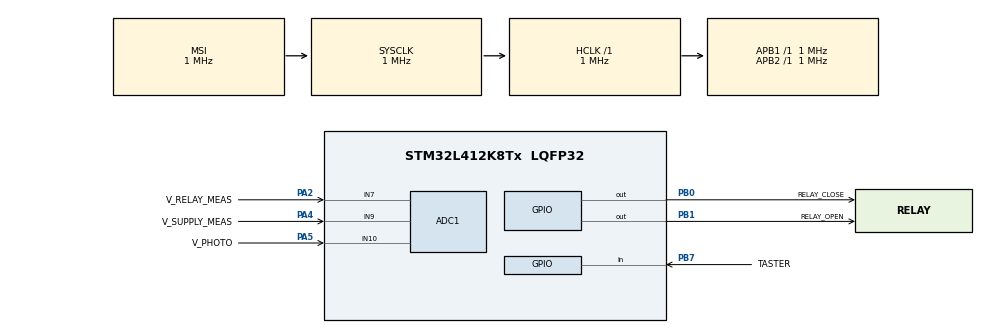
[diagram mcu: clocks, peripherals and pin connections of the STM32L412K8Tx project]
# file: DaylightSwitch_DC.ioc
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ADC1.Channel-0\#ChannelRegularConversion=ADC_CHANNEL_7
ADC1.Channel-1\#ChannelRegularConversion=ADC_CHANNEL_9
ADC1.Channel-2\#ChannelRegularConversion=ADC_CHANNEL_10
ADC1.Channel-3\#ChannelRegularConversion=ADC_CHANNEL_VREFINT
ADC1.ClockPrescaler=ADC_CLOCK_ASYNC_DIV4
ADC1.EOCSelection=ADC_EOC_SEQ_CONV
ADC1.NbrOfConversion=4
ADC1.NbrOfConversionFlag=1
ADC1.OffsetNumber-0\#ChannelRegularConversion=ADC_OFFSET_NONE
ADC1.OffsetNumber-1\#ChannelRegularConversion=ADC_OFFSET_NONE
ADC1.OffsetNumber-2\#ChannelRegularConversion=ADC_OFFSET_NONE
ADC1.OffsetNumber-3\#ChannelRegularConversion=ADC_OFFSET_NONE
ADC1.Overrun=ADC_OVR_DATA_OVERWRITTEN
ADC1.Rank-0\#ChannelRegularConversion=1
ADC1.Rank-1\#ChannelRegularConversion=2
ADC1.Rank-2\#ChannelRegularConversion=3
ADC1.Rank-3\#ChannelRegularConversion=4
ADC1.SamplingTime-0\#ChannelRegularConversion=ADC_SAMPLETIME_640CYCLES_5
ADC1.SamplingTime-1\#ChannelRegularConversion=ADC_SAMPLETIME_640CYCLES_5
ADC1.SamplingTime-2\#ChannelRegularConversion=ADC_SAMPLETIME_640CYCLES_5
ADC1.SamplingTime-3\#ChannelRegularConversion=ADC_SAMPLETIME_640CYCLES_5
ADC1.master=1
CRC.InputDataFormat=CRC_INPUTDATA_FORMAT_WORDS
Dma.ADC1.0.Direction=DMA_PERIPH_TO_MEMORY
Dma.ADC1.0.Instance=DMA1_Channel1
Dma.ADC1.0.MemDataAlignment=DMA_MDATAALIGN_HALFWORD
Dma.ADC1.0.MemInc=DMA_MINC_ENABLE
Dma.ADC1.0.Mode=DMA_NORMAL
Dma.ADC1.0.PeriphDataAlignment=DMA_PDATAALIGN_HALFWORD
Dma.ADC1.0.PeriphInc=DMA_PINC_DISABLE
Dma.ADC1.0.Priority=DMA_PRIORITY_MEDIUM
Dma.Request0=ADC1
Mcu.Family=STM32L4
Mcu.Name=STM32L412K8Tx
Mcu.Package=LQFP32
NVIC.ADC1_2_IRQn=true\:2\:0\:true\:false\:true\:true\:true
NVIC.DMA1_Channel1_IRQn=true\:0\:0\:true\:false\:true\:false\:true
NVIC.PriorityGroup=NVIC_PRIORITYGROUP_2
PA13\ (JTMS/SWDIO).Mode=Trace_Asynchronous_SW
PA13\ (JTMS/SWDIO).Signal=SYS_JTMS-SWDIO
PA14\ (JTCK/SWCLK).Mode=Trace_Asynchronous_SW
PA14\ (JTCK/SWCLK).Signal=SYS_JTCK-SWCLK
PA2.GPIO_Label=V_RELAY_MEAS
PA2.Signal=ADCx_IN7
PA4.GPIO_Label=V_SUPPLY_MEAS
PA4.Signal=ADCx_IN9
PA5.GPIO_Label=V_PHOTO
PA5.Signal=ADCx_IN10
PB0.GPIO_Label=RELAY_CLOSE
PB0.Signal=GPIO_Output
PB1.GPIO_Label=RELAY_OPEN
PB1.Signal=GPIO_Output
PB3\ (JTDO/TRACESWO).Mode=Trace_Asynchronous_SW
PB3\ (JTDO/TRACESWO).Signal=SYS_JTDO-SWO
PB7.GPIO_Label=TASTER
PB7.Signal=GPIO_Input
ProjectManager.HeapSize=0x600
ProjectManager.StackSize=0x600
ProjectManager.TargetToolchain=STM32CubeIDE
RCC.ADCFreq_Value=1000000
RCC.AHBFreq_Value=1000000
RCC.APB1Freq_Value=1000000
RCC.APB1TimFreq_Value=1000000
RCC.APB2Freq_Value=1000000
RCC.APB2TimFreq_Value=1000000
RCC.CortexFreq_Value=1000000
RCC.HCLKFreq_Value=1000000
RCC.HSE_VALUE=8000000
RCC.HSI48_VALUE=48000000
RCC.HSI_VALUE=16000000
RCC.LSE_VALUE=32768
RCC.MSIClockRange=RCC_MSIRANGE_4
RCC.MSI_VALUE=1000000
RCC.SYSCLKFreq_VALUE=1000000
RCC.USBFreq_Value=1000000
RCC.VCOOutputFreq_Value=8000000
SH.ADCx_IN10.0=ADC1_IN10,IN10-Single-Ended
SH.ADCx_IN7.0=ADC1_IN7,IN7-Single-Ended
SH.ADCx_IN9.0=ADC1_IN9,IN9-Single-Ended
VP_ADC1_Vref_Input.Mode=IN-Vrefint
VP_CRC_VS_CRC.Mode=CRC_Activate
board=custom

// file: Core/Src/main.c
/* USER CODE BEGIN Header */
/**
  ******************************************************************************
  * @file           : main.c
  * @brief          : Main program body
  ******************************************************************************
  * @attention
  *
  * <h2><center>&copy; Copyright (c) 2020 STMicroelectronics.
  * All rights reserved.</center></h2>
  *
  * This software component is licensed by ST under BSD 3-Clause license,
  * the "License"; You may not use this file except in compliance with the
  * License. You may obtain a copy of the License at:
  *                        opensource.org/licenses/BSD-3-Clause
  *
  ******************************************************************************
  */
/* USER CODE END Header */

#include "main.h"

ADC_HandleTypeDef hadc1;
DMA_HandleTypeDef hdma_adc1;

CRC_HandleTypeDef hcrc;

/* USER CODE BEGIN PV */
extern void doCpp(void);
/* USER CODE END PV */

void SystemClock_Config(void);
static void MX_GPIO_Init(void);
static void MX_DMA_Init(void);
static void MX_ADC1_Init(void);
static void MX_CRC_Init(void);

int main(void)
{
  /* USER CODE BEGIN 1 */
  CoreDebug->DEMCR |= CoreDebug_DEMCR_TRCENA_Msk;
  DWT->CYCCNT = 0;
  DWT->CTRL |= DWT_CTRL_CYCCNTENA_Msk;
  /* USER CODE END 1 */

  /* MCU Configuration--------------------------------------------------------*/

  /* Reset of all peripherals, Initializes the Flash interface and the Systick. */
  HAL_Init();

  /* Configure the system clock */
  SystemClock_Config();

  /* Initialize all configured peripherals */
  MX_GPIO_Init();
  MX_DMA_Init();
  MX_ADC1_Init();
  MX_CRC_Init();
  /* USER CODE BEGIN 2 */

  doCpp();  // --> This function should never return..
  /* USER CODE END 2 */

  /* Infinite loop */
  while (1)
  {

  }
}

void SystemClock_Config(void)
{
  RCC_OscInitTypeDef RCC_OscInitStruct = {0};
  RCC_ClkInitTypeDef RCC_ClkInitStruct = {0};
  RCC_PeriphCLKInitTypeDef PeriphClkInit = {0};

  /** Configure the main internal regulator output voltage
  */
  if (HAL_PWREx_ControlVoltageScaling(PWR_REGULATOR_VOLTAGE_SCALE1) != HAL_OK)
  {
    Error_Handler();
  }
  /** Initializes the CPU, AHB and APB busses clocks
  */
  RCC_OscInitStruct.OscillatorType = RCC_OSCILLATORTYPE_MSI;
  RCC_OscInitStruct.MSIState = RCC_MSI_ON;
  RCC_OscInitStruct.MSICalibrationValue = 0;
  RCC_OscInitStruct.MSIClockRange = RCC_MSIRANGE_4;
  RCC_OscInitStruct.PLL.PLLState = RCC_PLL_NONE;
  if (HAL_RCC_OscConfig(&RCC_OscInitStruct) != HAL_OK)
  {
    Error_Handler();
  }
  /** Initializes the CPU, AHB and APB busses clocks
  */
  RCC_ClkInitStruct.ClockType = RCC_CLOCKTYPE_HCLK|RCC_CLOCKTYPE_SYSCLK
                              |RCC_CLOCKTYPE_PCLK1|RCC_CLOCKTYPE_PCLK2;
  RCC_ClkInitStruct.SYSCLKSource = RCC_SYSCLKSOURCE_MSI;
  RCC_ClkInitStruct.AHBCLKDivider = RCC_SYSCLK_DIV1;
  RCC_ClkInitStruct.APB1CLKDivider = RCC_HCLK_DIV1;
  RCC_ClkInitStruct.APB2CLKDivider = RCC_HCLK_DIV1;

  if (HAL_RCC_ClockConfig(&RCC_ClkInitStruct, FLASH_LATENCY_0) != HAL_OK)
  {
    Error_Handler();
  }
  PeriphClkInit.PeriphClockSelection = RCC_PERIPHCLK_ADC;
  if (HAL_RCCEx_PeriphCLKConfig(&PeriphClkInit) != HAL_OK)
  {
    Error_Handler();
  }
}

static void MX_ADC1_Init(void)
{

  ADC_MultiModeTypeDef multimode = {0};
  ADC_ChannelConfTypeDef sConfig = {0};

  /** Common config
  */
  hadc1.Instance = ADC1;
  hadc1.Init.ClockPrescaler = ADC_CLOCK_ASYNC_DIV4;
  hadc1.Init.Resolution = ADC_RESOLUTION_12B;
  hadc1.Init.DataAlign = ADC_DATAALIGN_RIGHT;
  hadc1.Init.ScanConvMode = ADC_SCAN_ENABLE;
  hadc1.Init.EOCSelection = ADC_EOC_SEQ_CONV;
  hadc1.Init.LowPowerAutoWait = DISABLE;
  hadc1.Init.ContinuousConvMode = DISABLE;
  hadc1.Init.NbrOfConversion = 4;
  hadc1.Init.DiscontinuousConvMode = DISABLE;
  hadc1.Init.NbrOfDiscConversion = 1;
  hadc1.Init.ExternalTrigConv = ADC_SOFTWARE_START;
  hadc1.Init.ExternalTrigConvEdge = ADC_EXTERNALTRIGCONVEDGE_NONE;
  hadc1.Init.DMAContinuousRequests = DISABLE;
  hadc1.Init.Overrun = ADC_OVR_DATA_OVERWRITTEN;
  hadc1.Init.OversamplingMode = DISABLE;
  if (HAL_ADC_Init(&hadc1) != HAL_OK)
  {
    Error_Handler();
  }
  /** Configure the ADC multi-mode
  */
  multimode.Mode = ADC_MODE_INDEPENDENT;
  if (HAL_ADCEx_MultiModeConfigChannel(&hadc1, &multimode) != HAL_OK)
  {
    Error_Handler();
  }
  /** Configure Regular Channel
  */
  sConfig.Channel = ADC_CHANNEL_7;
  sConfig.Rank = ADC_REGULAR_RANK_1;
  sConfig.SamplingTime = ADC_SAMPLETIME_640CYCLES_5;
  sConfig.SingleDiff = ADC_SINGLE_ENDED;
  sConfig.OffsetNumber = ADC_OFFSET_NONE;
  sConfig.Offset = 0;
  if (HAL_ADC_ConfigChannel(&hadc1, &sConfig) != HAL_OK)
  {
    Error_Handler();
  }
  /** Configure Regular Channel
  */
  sConfig.Channel = ADC_CHANNEL_9;
  sConfig.Rank = ADC_REGULAR_RANK_2;
  if (HAL_ADC_ConfigChannel(&hadc1, &sConfig) != HAL_OK)
  {
    Error_Handler();
  }
  /** Configure Regular Channel
  */
  sConfig.Channel = ADC_CHANNEL_10;
  sConfig.Rank = ADC_REGULAR_RANK_3;
  if (HAL_ADC_ConfigChannel(&hadc1, &sConfig) != HAL_OK)
  {
    Error_Handler();
  }
  /** Configure Regular Channel
  */
  sConfig.Channel = ADC_CHANNEL_VREFINT;
  sConfig.Rank = ADC_REGULAR_RANK_4;
  if (HAL_ADC_ConfigChannel(&hadc1, &sConfig) != HAL_OK)
  {
    Error_Handler();
  }

}

static void MX_CRC_Init(void)
{

  hcrc.Instance = CRC;
  hcrc.Init.DefaultInitValueUse = DEFAULT_INIT_VALUE_ENABLE;
  hcrc.Init.InputDataInversionMode = CRC_INPUTDATA_INVERSION_NONE;
  hcrc.Init.OutputDataInversionMode = CRC_OUTPUTDATA_INVERSION_DISABLE;
  hcrc.InputDataFormat = CRC_INPUTDATA_FORMAT_WORDS;
  if (HAL_CRC_Init(&hcrc) != HAL_OK)
  {
    Error_Handler();
  }

}

static void MX_DMA_Init(void)
{

  /* DMA controller clock enable */
  __HAL_RCC_DMA1_CLK_ENABLE();

  /* DMA interrupt init */
  /* DMA1_Channel1_IRQn interrupt configuration */
  HAL_NVIC_SetPriority(DMA1_Channel1_IRQn, 0, 0);
  HAL_NVIC_EnableIRQ(DMA1_Channel1_IRQn);

}

static void MX_GPIO_Init(void)
{
  GPIO_InitTypeDef GPIO_InitStruct = {0};

  /* GPIO Ports Clock Enable */
  __HAL_RCC_GPIOC_CLK_ENABLE();
  __HAL_RCC_GPIOA_CLK_ENABLE();
  __HAL_RCC_GPIOB_CLK_ENABLE();
  __HAL_RCC_GPIOH_CLK_ENABLE();

  /*Configure GPIO pin Output Level */
  HAL_GPIO_WritePin(GPIOB, RELAY_CLOSE_Pin|RELAY_OPEN_Pin, GPIO_PIN_RESET);

  /*Configure GPIO pins : PC14 PC15 */
  GPIO_InitStruct.Pin = GPIO_PIN_14|GPIO_PIN_15;
  GPIO_InitStruct.Mode = GPIO_MODE_ANALOG;
  GPIO_InitStruct.Pull = GPIO_NOPULL;
  HAL_GPIO_Init(GPIOC, &GPIO_InitStruct);

  /*Configure GPIO pins : PA0 PA1 PA3 PA6
                           PA7 PA8 PA9 PA10
                           PA11 PA12 PA15 */
  GPIO_InitStruct.Pin = GPIO_PIN_0|GPIO_PIN_1|GPIO_PIN_3|GPIO_PIN_6
                          |GPIO_PIN_7|GPIO_PIN_8|GPIO_PIN_9|GPIO_PIN_10
                          |GPIO_PIN_11|GPIO_PIN_12|GPIO_PIN_15;
  GPIO_InitStruct.Mode = GPIO_MODE_ANALOG;
  GPIO_InitStruct.Pull = GPIO_NOPULL;
  HAL_GPIO_Init(GPIOA, &GPIO_InitStruct);

  /*Configure GPIO pins : RELAY_CLOSE_Pin RELAY_OPEN_Pin */
  GPIO_InitStruct.Pin = RELAY_CLOSE_Pin|RELAY_OPEN_Pin;
  GPIO_InitStruct.Mode = GPIO_MODE_OUTPUT_PP;
  GPIO_InitStruct.Pull = GPIO_NOPULL;
  GPIO_InitStruct.Speed = GPIO_SPEED_FREQ_LOW;
  HAL_GPIO_Init(GPIOB, &GPIO_InitStruct);

  /*Configure GPIO pins : PB4 PB5 PB6 */
  GPIO_InitStruct.Pin = GPIO_PIN_4|GPIO_PIN_5|GPIO_PIN_6;
  GPIO_InitStruct.Mode = GPIO_MODE_ANALOG;
  GPIO_InitStruct.Pull = GPIO_NOPULL;
  HAL_GPIO_Init(GPIOB, &GPIO_InitStruct);

  /*Configure GPIO pin : TASTER_Pin */
  GPIO_InitStruct.Pin = TASTER_Pin;
  GPIO_InitStruct.Mode = GPIO_MODE_INPUT;
  GPIO_InitStruct.Pull = GPIO_NOPULL;
  HAL_GPIO_Init(TASTER_GPIO_Port, &GPIO_InitStruct);

  /*Configure GPIO pin : PH3 */
  GPIO_InitStruct.Pin = GPIO_PIN_3;
  GPIO_InitStruct.Mode = GPIO_MODE_ANALOG;
  GPIO_InitStruct.Pull = GPIO_NOPULL;
  HAL_GPIO_Init(GPIOH, &GPIO_InitStruct);

}

void Error_Handler(void)
{
}

/************************ (C) COPYRIGHT STMicroelectronics *****END OF FILE****/
